# STM32H747ZIY6@M7 register map
File version: 1.0
Registers are 32-bit, access not given, reset 0x0 unless marked. A register's access mark holds for its fields unless they carry their own. Offsets are from the block's base; [hi:lo] are bit positions; {n}, {i} and the like mark numbered series; 'fields as' and 'values as' point back to an identical list.

## EXTI_D1
Base 0x58000080
Same registers: EXTI_D2 0x580000C0
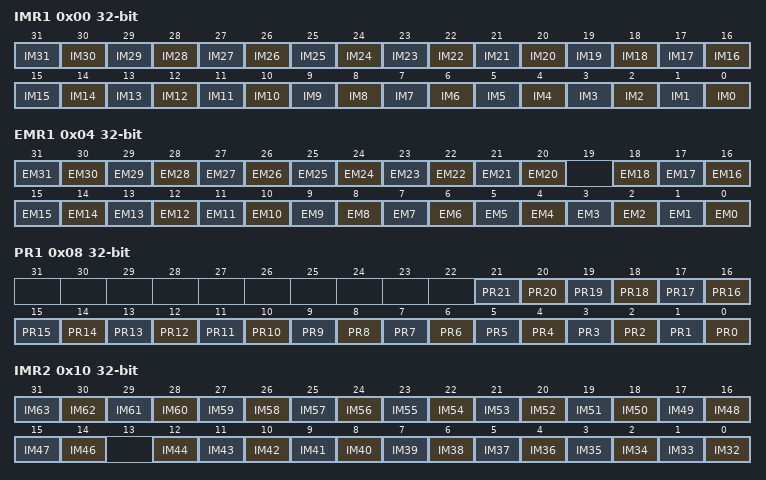
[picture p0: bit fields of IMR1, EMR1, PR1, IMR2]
0x00 IMR1
  [n] IM{n} (n=0..31)
0x04 EMR1
  [n] EM{n} (n=20..31), [n] EM{n} (n=0..18)
0x08 PR1
  [n] PR{n} (n=0..21)
0x10 IMR2
  [n-32] IM{n} (n=46..63), [n-32] IM{n} (n=32..44)
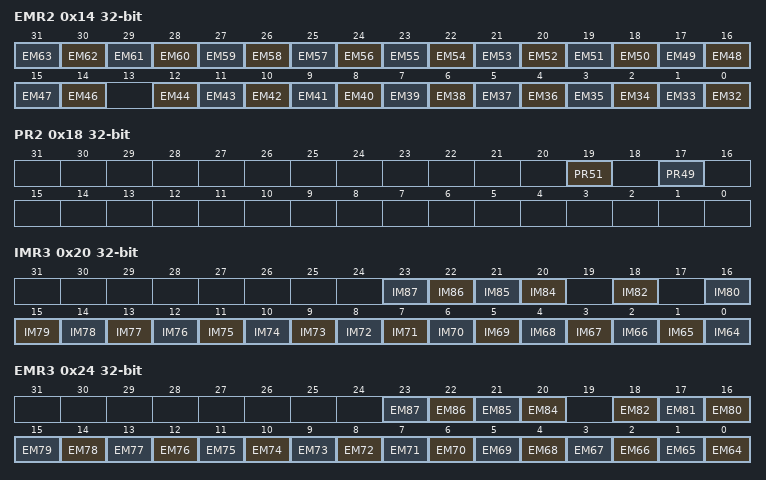
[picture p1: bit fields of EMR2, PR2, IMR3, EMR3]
0x14 EMR2
  [n-32] EM{n} (n=46..63), [n-32] EM{n} (n=32..44)
0x18 PR2
  [19] PR51, [17] PR49
0x20 IMR3
  [n-64] IM{n} (n=84..87), [18] IM82, [n-64] IM{n} (n=64..80)
0x24 EMR3
  [n-64] EM{n} (n=84..87), [n-64] EM{n} (n=64..82)
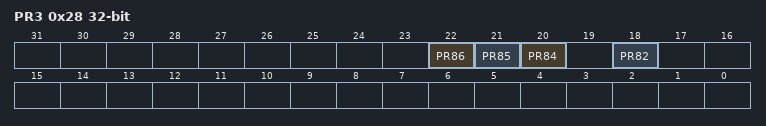
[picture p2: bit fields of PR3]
0x28 PR3
  [22] PR86, [21] PR85, [20] PR84, [18] PR82

## SYSCFG
Base 0x58000400
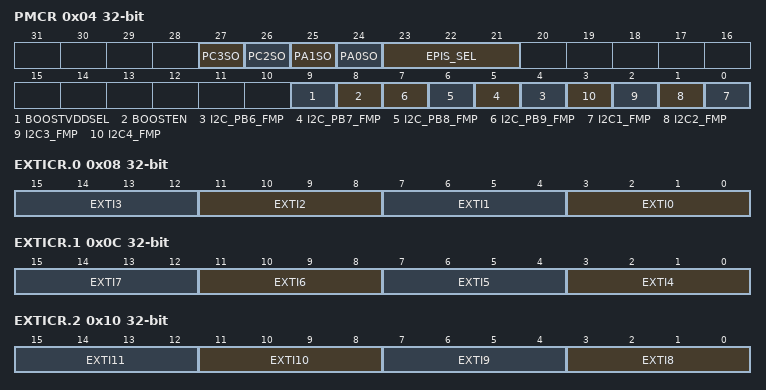
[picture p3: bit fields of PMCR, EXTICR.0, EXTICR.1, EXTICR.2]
0x04 PMCR
  [27] PC3SO, [26] PC2SO, [25] PA1SO, [24] PA0SO, [23:21] EPIS_SEL, [9] BOOSTVDDSEL, [8] BOOSTEN, [n-2] I2C_PB{n}_FMP (n=6..9), [n-1] I2C{n}_FMP (n=1..4)
0x08 EXTICR.0
  [4n+3:4n] EXTI{n} (n=0..3)
0x0C EXTICR.1
  [4n-13:4n-16] EXTI{n} (n=4..7)
0x10 EXTICR.2
  [4n-29:4n-32] EXTI{n} (n=8..11)
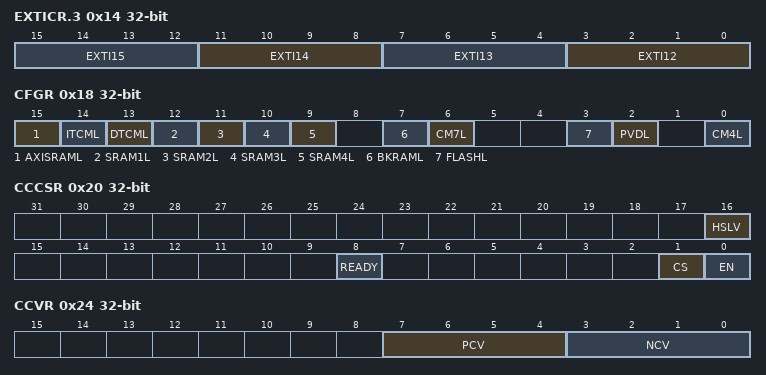
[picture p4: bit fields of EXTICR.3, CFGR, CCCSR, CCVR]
0x14 EXTICR.3
  [4n-45:4n-48] EXTI{n} (n=12..15)
0x18 CFGR
  [15] AXISRAML, [14] ITCML, [13] DTCML, [13-n] SRAM{n}L (n=1..4), [7] BKRAML, [6] CM7L, [3] FLASHL, [2] PVDL, [0] CM4L
0x20 CCCSR
  [16] HSLV, [8] READY, [1] CS, [0] EN
0x24 CCVR
  [7:4] PCV, [3:0] NCV
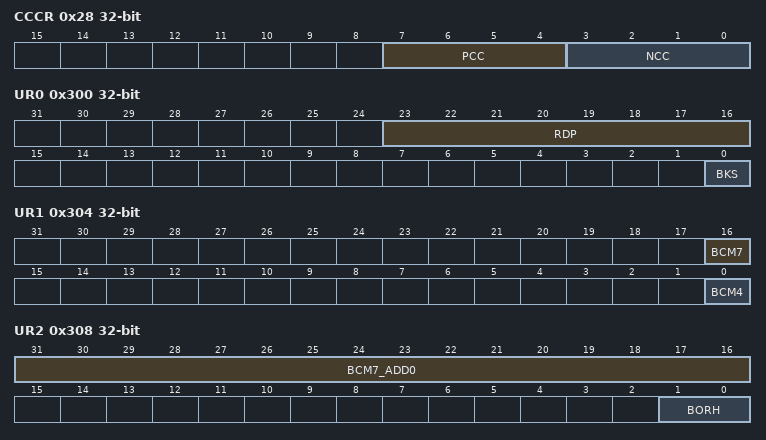
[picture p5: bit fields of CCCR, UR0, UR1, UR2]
0x28 CCCR
  [7:4] PCC, [3:0] NCC
0x2C PWRCR
  [0] ODEN
0x124 PKGR
  [3:0] PKG
0x300 UR0
  [23:16] RDP, [0] BKS
0x304 UR1
  [16] BCM7, [0] BCM4
0x308 UR2
  [31:16] BCM7_ADD0, [1:0] BORH
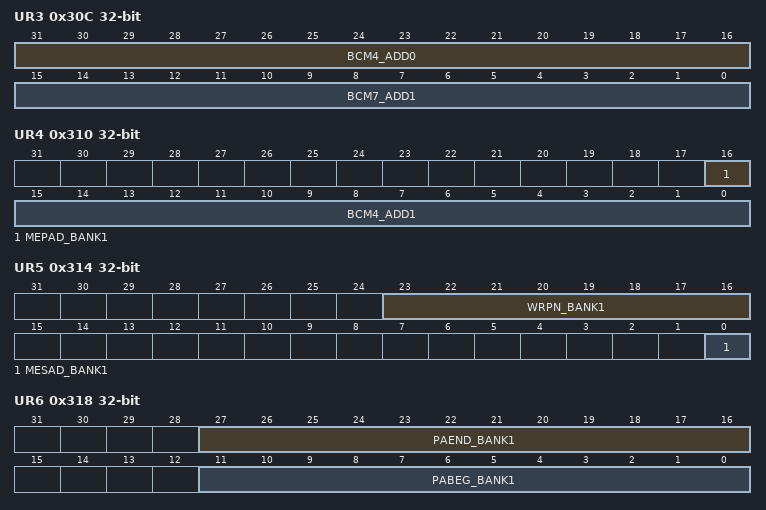
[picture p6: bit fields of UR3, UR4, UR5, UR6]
0x30C UR3
  [31:16] BCM4_ADD0, [15:0] BCM7_ADD1
0x310 UR4
  [16] MEPAD_BANK1, [15:0] BCM4_ADD1
0x314 UR5
  [23:16] WRPN_BANK1, [0] MESAD_BANK1
0x318 UR6
  [27:16] PAEND_BANK1, [11:0] PABEG_BANK1
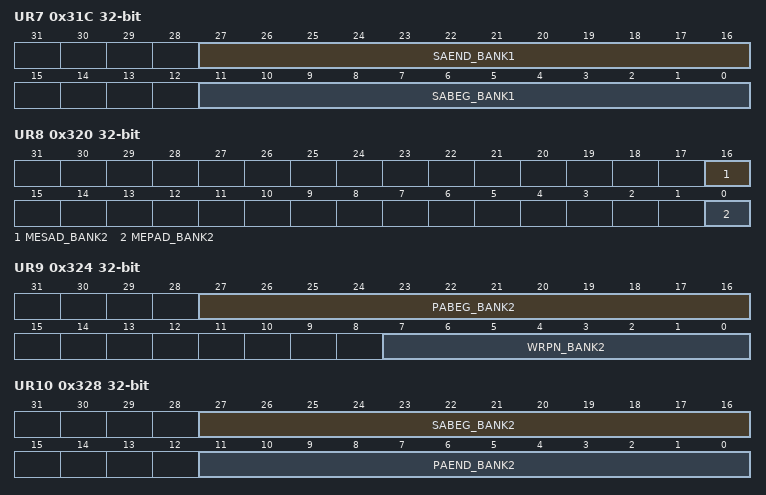
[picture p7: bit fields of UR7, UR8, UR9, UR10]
0x31C UR7
  [27:16] SAEND_BANK1, [11:0] SABEG_BANK1
0x320 UR8
  [16] MESAD_BANK2, [0] MEPAD_BANK2
0x324 UR9
  [27:16] PABEG_BANK2, [7:0] WRPN_BANK2
0x328 UR10
  [27:16] SABEG_BANK2, [11:0] PAEND_BANK2
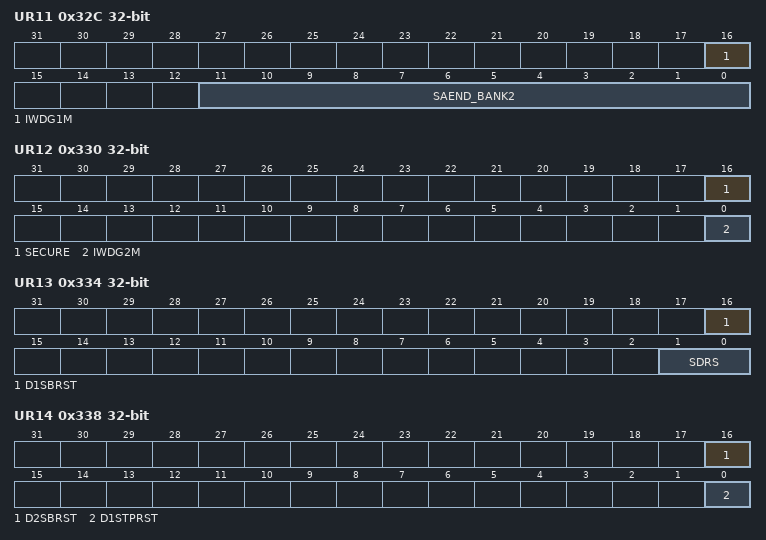
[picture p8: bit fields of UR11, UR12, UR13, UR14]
0x32C UR11
  [16] IWDG1M, [11:0] SAEND_BANK2
0x330 UR12
  [16] SECURE, [0] IWDG2M
0x334 UR13
  [16] D1SBRST, [1:0] SDRS
0x338 UR14
  [16] D2SBRST, [0] D1STPRST
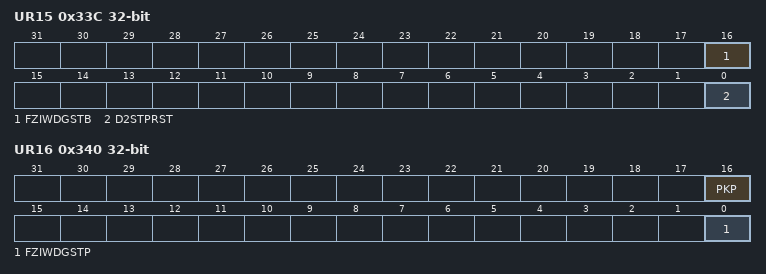
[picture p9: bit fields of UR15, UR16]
0x33C UR15
  [16] FZIWDGSTB, [0] D2STPRST
0x340 UR16
  [16] PKP, [0] FZIWDGSTP
0x344 UR17
  [0] IOHSLV

## COMP12
Base 0x58003800
0x00 SR
0x04 ICFR
0x08 OR

## COMP1
Base 0x5800380C
Same registers: COMP2 0x58003810, COMP12_COMMON 0x58003810
0x00 CFGR

## VREFBUF
Base 0x58003C00
0x00 CSR
  [5] VRS_OUT3, [5:4] VRS_OUT4, [3] VRR, [1] HIZ, [0] ENVR
0x04 CCR
  [5:0] TRIM

## RTC
Base 0x58004000
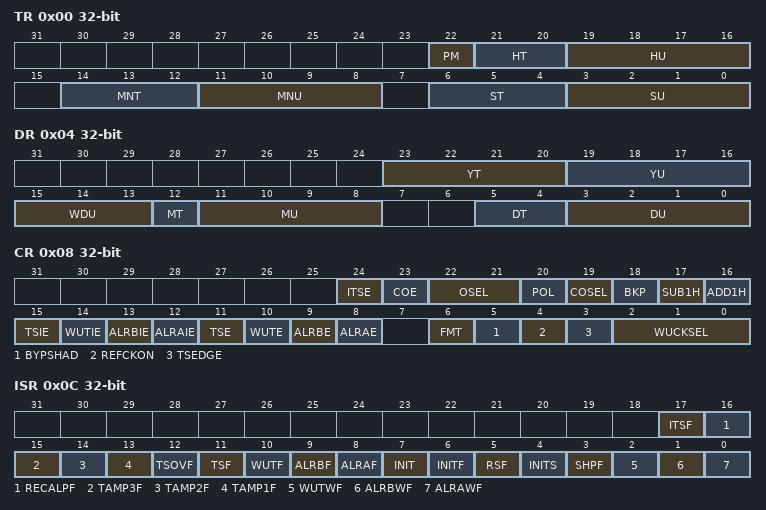
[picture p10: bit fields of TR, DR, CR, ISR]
0x00 TR
  [22] PM, [21:20] HT, [19:16] HU, [14:12] MNT, [11:8] MNU, [6:4] ST, [3:0] SU
0x04 DR
  [23:20] YT, [19:16] YU, [15:13] WDU, [12] MT, [11:8] MU, [5:4] DT, [3:0] DU
0x08 CR
  [24] ITSE, [23] COE, [22:21] OSEL, [20] POL, [19] COSEL, [18] BKP, [17] SUB1H, [16] ADD1H, [15] TSIE, [14] WUTIE, [13] ALRBIE, [12] ALRAIE, [11] TSE, [10] WUTE, [9] ALRBE, [8] ALRAE, [6] FMT, [5] BYPSHAD, [4] REFCKON, [3] TSEDGE, [2:0] WUCKSEL
0x0C ISR
  [17] ITSF, [16] RECALPF, [15] TAMP3F, [14] TAMP2F, [13] TAMP1F, [12] TSOVF, [11] TSF, [10] WUTF, [9] ALRBF, [8] ALRAF, [7] INIT, [6] INITF, [5] RSF, [4] INITS, [3] SHPF, [2] WUTWF, [1] ALRBWF, [0] ALRAWF
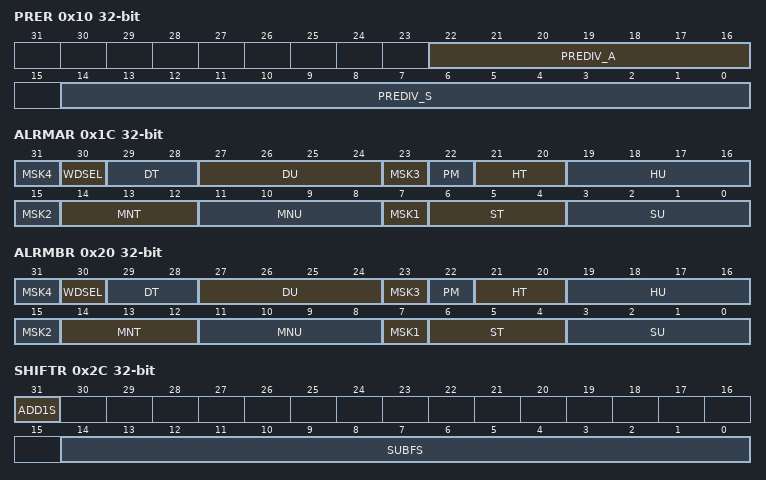
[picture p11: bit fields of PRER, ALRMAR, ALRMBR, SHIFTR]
0x10 PRER
  [22:16] PREDIV_A, [14:0] PREDIV_S
0x14 WUTR
  [15:0] WUT
0x1C ALRMAR
  [8n-1] MSK{n} (n=1..4), [30] WDSEL, [29:28] DT, [27:24] DU, [22] PM, [21:20] HT, [19:16] HU, [14:12] MNT, [11:8] MNU, [6:4] ST, [3:0] SU
0x20 ALRMBR
  fields as ALRMAR
0x24 WPR
  [7:0] KEY
0x28 SSR
  [15:0] SS
0x2C SHIFTR
  [31] ADD1S, [14:0] SUBFS
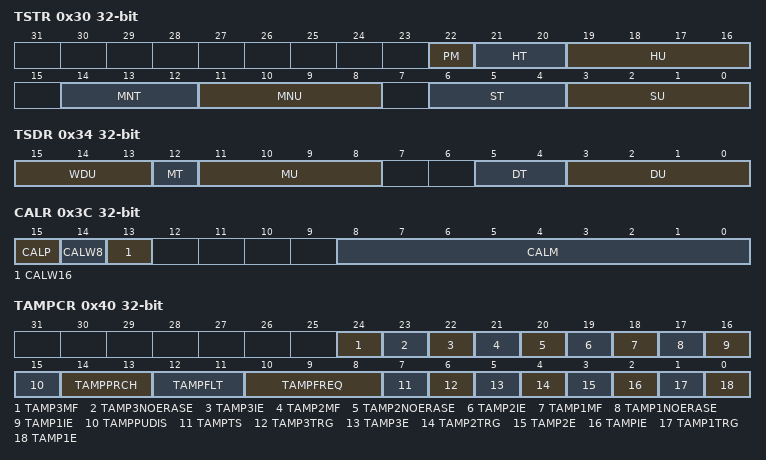
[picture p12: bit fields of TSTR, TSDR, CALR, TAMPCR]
0x30 TSTR
  fields as TR
0x34 TSDR
  [15:13] WDU, [12] MT, [11:8] MU, [5:4] DT, [3:0] DU
0x38 TSSSR
  [15:0] SS
0x3C CALR
  [15] CALP, [14] CALW8, [13] CALW16, [8:0] CALM
0x40 TAMPCR
  [24] TAMP3MF, [23] TAMP3NOERASE, [22] TAMP3IE, [21] TAMP2MF, [20] TAMP2NOERASE, [19] TAMP2IE, [18] TAMP1MF, [17] TAMP1NOERASE, [16] TAMP1IE, [15] TAMPPUDIS, [14:13] TAMPPRCH, [12:11] TAMPFLT, [10:8] TAMPFREQ, [7] TAMPTS, [6] TAMP3TRG, [5] TAMP3E, [4] TAMP2TRG, [3] TAMP2E, [2] TAMPIE, [1] TAMP1TRG, [0] TAMP1E
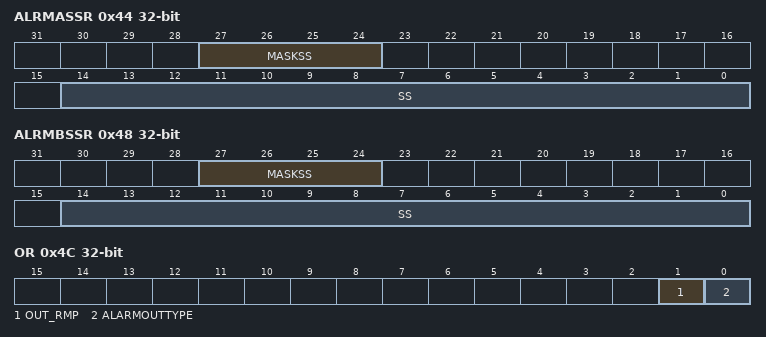
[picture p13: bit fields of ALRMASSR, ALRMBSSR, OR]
0x44 ALRMASSR
  [27:24] MASKSS, [14:0] SS
0x48 ALRMBSSR
  [27:24] MASKSS, [14:0] SS
0x4C OR
  [1] OUT_RMP, [0] ALARMOUTTYPE
{0x50+4i} BKP{i}R (i=0..31)
